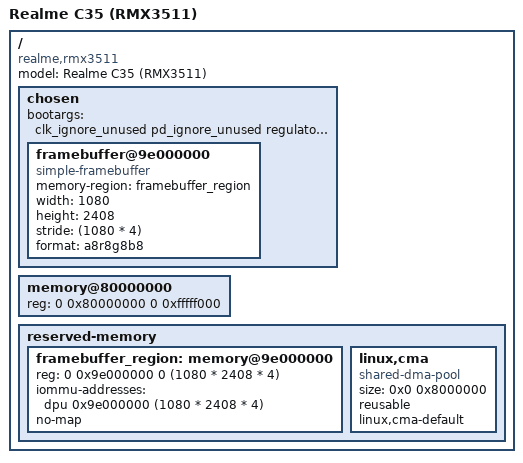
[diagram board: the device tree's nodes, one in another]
// SPDX-License-Identifier: (GPL-2.0 OR MIT)
/*
 * Copyright (C) 2026 faveoled
 */

/dts-v1/;

#include "ums9230.dtsi"

/ {
	model = "Realme C35 (RMX3511)";
	compatible = "realme,rmx3511", "sprd,ums9230";

	chosen {
		#address-cells = <2>;
		#size-cells = <2>;
		ranges;

		bootargs = "clk_ignore_unused pd_ignore_unused regulator_ignore_unused pmos.nosplash";

		framebuffer@9e000000 {
			compatible = "simple-framebuffer";
			memory-region = <&framebuffer_region>;			
			width = <1080>;
			height = <2408>;
			stride = <(1080 * 4)>;
			format = "a8r8g8b8";
		};


	};

	memory@80000000 {
		device_type = "memory";
		reg = <0 0x80000000 0 0xfffff000>;
	};

	reserved-memory {

		framebuffer_region: memory@9e000000 {
			reg = <0 0x9e000000 0 (1080 * 2408 * 4)>;
			iommu-addresses = <&dpu 0x9e000000 (1080 * 2408 * 4)>;
			no-map;
		};

		linux,cma {
			compatible = "shared-dma-pool";
			size = <0x0 0x8000000>;
			reusable;
			linux,cma-default;
		};
	};
};



